# CY8C5868AXI_LP035 register map
File version: 0.1
CY8C58LP
Registers are 8-bit, read-write, no defined reset value unless marked. A register's access mark holds for its fields unless they carry their own. Offsets are from the block's base; lines under a group give offsets from that group; [hi:lo] are bit positions; {n}, {i} and the like mark numbered series; 'fields as' and 'values as' point back to an identical list; <NAME> marks a mode.

## Memory map
0x00000000 MIDI1_UART — UART
0x00000000 SleepTimer
0x00000000 USB — USBFS
0x00000000 MIDI2_UART — UART

## MIDI1_UART — UART
Base 0x00000000
0x40006427 RX_MIDI1_UART_RX_ADDRESS1 — RX Address1 Register
0x40006437 RX_MIDI1_UART_RX_ADDRESS2 — RX Address2 Register
0x40006447 RX_MIDI1_UART_RX_DATA — RX Data Register
0x40006544 TX_MIDI1_UART_TX_DATA — TX Data Register
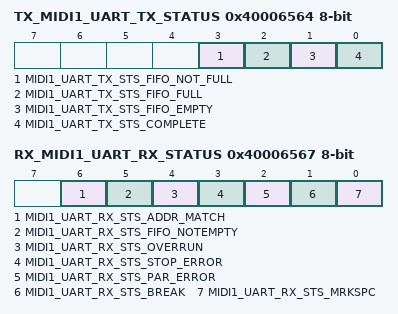
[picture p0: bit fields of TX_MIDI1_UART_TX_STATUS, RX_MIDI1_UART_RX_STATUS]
0x40006564 TX_MIDI1_UART_TX_STATUS — TX status register
  [3] MIDI1_UART_TX_STS_FIFO_NOT_FULL ro, [2] MIDI1_UART_TX_STS_FIFO_FULL ro, [1] MIDI1_UART_TX_STS_FIFO_EMPTY ro, [0] MIDI1_UART_TX_STS_COMPLETE ro
0x40006567 RX_MIDI1_UART_RX_STATUS — RX status register
  [6] MIDI1_UART_RX_STS_ADDR_MATCH ro, [5] MIDI1_UART_RX_STS_FIFO_NOTEMPTY ro, [4] MIDI1_UART_RX_STS_OVERRUN ro, [3] MIDI1_UART_RX_STS_STOP_ERROR ro, [2] MIDI1_UART_RX_STS_PAR_ERROR ro, [1] MIDI1_UART_RX_STS_BREAK ro, [0] MIDI1_UART_RX_STS_MRKSPC ro

## SleepTimer
Base 0x00000000
0x40004381 SleepTimer_CTW_INTERVAL_REG — Timewheel Configuration Register 1
  [3:0] ctw_interval — Sets the central timewheel interval.
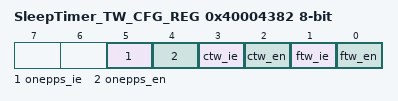
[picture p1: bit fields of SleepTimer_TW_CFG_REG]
0x40004382 SleepTimer_TW_CFG_REG — Timewheel Configuration Register 2
  [5] onepps_ie — When set and one pulse-per-second is enabled, an interrupt is issued when the pulse occurs.
    1=Enabled (One PPS interrupt is enabled); 0=Disabled (One PPS interrupt is disabled)
  [4] onepps_en — When set, the system returns to the active global power mode once every second.
    1=Enabled (One PPS is enabled); 0=Disabled (One PPS is disabled)
  [3] ctw_ie — When set and the central timewheel is enabled, an interrupt is issued when the central timewheel reaches the selected interval.
    1=Enabled (CTW interrupt is enabled); 0=Disabled (CTW interrupt is disabled)
  [2] ctw_en — When set, the system returns to the active global power mode when the central timewheel reaches the selected interval.
    1=Enabled (CTW is enabled); 0=Disabled (CTW is disabled)
  [1] ftw_ie — When set and the fast timewheel is enabled, an interrupt is issued when it reaches the terminal count.
    1=Enabled (FTW interrupt is enabled); 0=Disabled (FTW interrupt is disabled)
  [0] ftw_en — When set, the system returns to the active global power mode when the fast timewheel reaches the selected interval.
    1=Enabled (FTW is enabled); 0=Disabled (FTW is disabled)

## MIDI2_UART — UART
Base 0x00000000
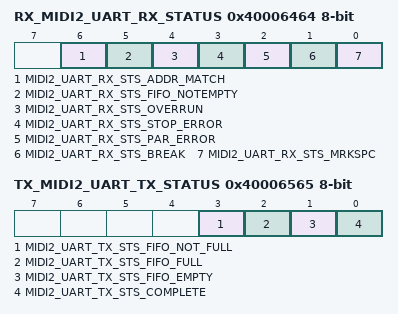
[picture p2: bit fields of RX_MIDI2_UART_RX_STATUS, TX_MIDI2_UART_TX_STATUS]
0x40006464 RX_MIDI2_UART_RX_STATUS — RX status register
  [6] MIDI2_UART_RX_STS_ADDR_MATCH ro, [5] MIDI2_UART_RX_STS_FIFO_NOTEMPTY ro, [4] MIDI2_UART_RX_STS_OVERRUN ro, [3] MIDI2_UART_RX_STS_STOP_ERROR ro, [2] MIDI2_UART_RX_STS_PAR_ERROR ro, [1] MIDI2_UART_RX_STS_BREAK ro, [0] MIDI2_UART_RX_STS_MRKSPC ro
0x40006526 RX_MIDI2_UART_RX_ADDRESS1 — RX Address1 Register
0x40006536 RX_MIDI2_UART_RX_ADDRESS2 — RX Address2 Register
0x40006545 TX_MIDI2_UART_TX_DATA — TX Data Register
0x40006546 RX_MIDI2_UART_RX_DATA — RX Data Register
0x40006565 TX_MIDI2_UART_TX_STATUS — TX status register
  [3] MIDI2_UART_TX_STS_FIFO_NOT_FULL ro, [2] MIDI2_UART_TX_STS_FIFO_FULL ro, [1] MIDI2_UART_TX_STS_FIFO_EMPTY ro, [0] MIDI2_UART_TX_STS_COMPLETE ro
